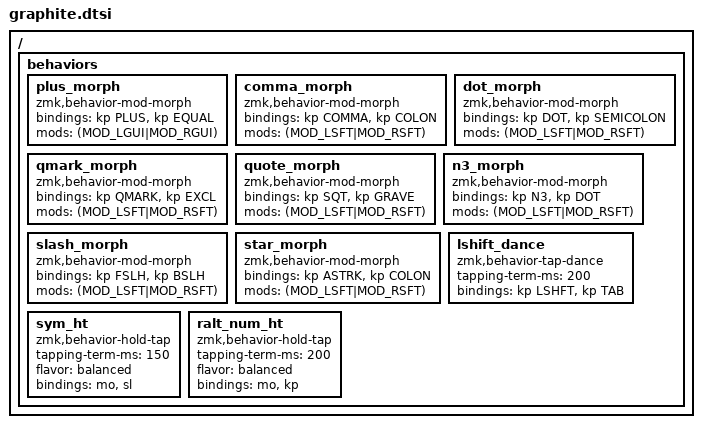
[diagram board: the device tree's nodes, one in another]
/*
 * Graphite Layout - Shared base layer definitions
 * https://github.com/rdavison/graphite-layout
 *
 * Standard Corne (36 keys):
 *   Uses GRAPHITE_BASE_36, GRAPHITE_SYM_36, GRAPHITE_NUM_36, GRAPHITE_SYS_36
 *
 * TOTEM (38 keys):
 *   Uses GRAPHITE_BASE_38, GRAPHITE_SYM_38, GRAPHITE_FUN_38, GRAPHITE_SYS_38
 *
 * Eyelash Corne (42 keys + encoder):
 *   Uses GRAPHITE_BASE_42, GRAPHITE_SYM_42, GRAPHITE_NUM_42, GRAPHITE_SYS_42
 */

// Layer indices
#define BASE 0
#define NUM 1
#define FUN 1  // Corne uses FUN at same index as NUM
#define SYM 2
#define SYS 3
#define NUMSYM 4  // Numpad overlay above SYM (accessed via SYM + %)

/ {
    behaviors {
        plus_morph: plus_morph {
            compatible = "zmk,behavior-mod-morph";
            #binding-cells = <0>;
            bindings = <&kp PLUS>, <&kp EQUAL>;
            mods = <(MOD_LGUI|MOD_RGUI)>;
        };

        comma_morph: comma_morph {
            compatible = "zmk,behavior-mod-morph";
            #binding-cells = <0>;
            bindings = <&kp COMMA>, <&kp COLON>;
            mods = <(MOD_LSFT|MOD_RSFT)>;
        };

        dot_morph: dot_morph {
            compatible = "zmk,behavior-mod-morph";
            #binding-cells = <0>;
            bindings = <&kp DOT>, <&kp SEMICOLON>;
            mods = <(MOD_LSFT|MOD_RSFT)>;
        };

        qmark_morph: qmark_morph {
            compatible = "zmk,behavior-mod-morph";
            #binding-cells = <0>;
            bindings = <&kp QMARK>, <&kp EXCL>;
            mods = <(MOD_LSFT|MOD_RSFT)>;
        };

        quote_morph: quote_morph {
            compatible = "zmk,behavior-mod-morph";
            #binding-cells = <0>;
            bindings = <&kp SQT>, <&kp GRAVE>;
            mods = <(MOD_LSFT|MOD_RSFT)>;
        };

        n3_morph: n3_morph {
            compatible = "zmk,behavior-mod-morph";
            #binding-cells = <0>;
            bindings = <&kp N3>, <&kp DOT>;
            mods = <(MOD_LSFT|MOD_RSFT)>;
        };

        slash_morph: slash_morph {
            compatible = "zmk,behavior-mod-morph";
            #binding-cells = <0>;
            bindings = <&kp FSLH>, <&kp BSLH>;
            mods = <(MOD_LSFT|MOD_RSFT)>;
        };

        star_morph: star_morph {
            compatible = "zmk,behavior-mod-morph";
            #binding-cells = <0>;
            bindings = <&kp ASTRK>, <&kp COLON>;
            mods = <(MOD_LSFT|MOD_RSFT)>;
        };

        lshift_dance: lshift_dance {
            compatible = "zmk,behavior-tap-dance";
            #binding-cells = <0>;
            tapping-term-ms = <200>;
            bindings = <&kp LSHFT>, <&kp TAB>;
        };

        sym_ht: sym_ht {
            compatible = "zmk,behavior-hold-tap";
            #binding-cells = <2>;
            tapping-term-ms = <150>;
            flavor = "balanced";
            bindings = <&mo>, <&sl>;
        };

        ralt_num_ht: ralt_num_ht {
            compatible = "zmk,behavior-hold-tap";
            #binding-cells = <2>;
            tapping-term-ms = <200>;
            flavor = "balanced";
            bindings = <&mo>, <&kp>;
        };
    };
};

// ============================================================================
// 36-KEY LAYOUTS (Standard Corne)
// ============================================================================

#define GRAPHITE_BASE_36 \
   &none           &kp B          &kp L           &kp D           &kp W           &kp Z        &kp SEMI      &kp F           &kp O           &kp U           &kp J           &none          \
   &none           &kp N          &kp R           &kp T           &kp S           &kp G        &kp Y         &kp H           &kp A           &kp E           &kp I           &none          \
   &lshift_dance   &kp Q          &kp X           &kp M           &kp C           &kp V        &kp K         &kp P           &kp COMMA       &kp DOT         &kp FSLH        &kp RSHFT      \
                                               &mt LCTRL ESC   &sym_ht SYM SYM &kp SPC      &kp RET       &kp BSPC        &ralt_num_ht NUM RALT

#define GRAPHITE_SYM_36 \
   &trans          &kp EXCL       &kp LPAR        &kp RPAR        &kp AMPS        &kp GRAVE    &kp COLON     &kp EQUAL       &kp MINUS       &kp PLUS        &kp UNDER       &trans         \
   &trans          &kp ASTRK      &kp LBRC        &kp RBRC        &kp HASH        &kp DOLLAR   &kp PG_UP     &kp LEFT        &kp DOWN        &kp UP          &kp RIGHT       &trans         \
   &trans          &kp CARET      &kp LBKT        &kp RBKT        &kp AT_SIGN     &mo NUMSYM   &kp PG_DN     &kp HOME        &kp END         &kp SQT         &kp BSLH        &trans         \
                                               &kp LCTRL       &trans          &trans       &trans        &kp DEL         &kp LGUI

#define GRAPHITE_NUM_36 \
   &trans          &kp HOME       &kp PG_UP       &kp PG_DN       &kp END         &trans       &star_morph   &kp N7          &kp N8          &kp N9          &kp MINUS       &trans         \
   &trans          &kp LEFT       &kp UP          &kp DOWN        &kp RIGHT       &trans       &kp EQUAL     &kp N4          &kp N5          &kp N6          &kp PLUS        &trans         \
   &kp TAB         &trans         &trans          &trans          &trans          &trans       &kp N0        &kp N1          &kp N2          &n3_morph       &slash_morph    &trans         \
                                               &trans          &trans          &trans       &kp RET       &trans          &trans

#define GRAPHITE_SYS_36 \
   &trans          &out OUT_TOG   &trans          &trans          &trans          &trans       &trans        &kp C_PP        &kp C_NEXT      &trans          &trans          &trans         \
   &trans          &kp PSCRN      &bt BT_SEL 0    &bt BT_SEL 1    &bt BT_SEL 2    &bt BT_SEL 3 &trans        &kp C_VOL_DN    &kp C_VOL_UP    &kp C_BRI_DN    &kp C_BRI_UP    &trans         \
   &trans          &trans         &trans          &trans          &trans          &trans       &trans        &trans          &bt BT_CLR_ALL  &trans          &trans          &trans         \
                                               &trans          &trans          &trans       &trans        &trans          &trans

#define GRAPHITE_NUMSYM_36 \
   &trans          &trans         &trans          &trans          &trans          &trans       &star_morph   &kp N7          &kp N8          &kp N9          &kp MINUS       &trans         \
   &trans          &trans         &trans          &trans          &trans          &trans       &kp EQUAL     &kp N4          &kp N5          &kp N6          &kp PLUS        &trans         \
   &trans          &trans         &trans          &trans          &trans          &trans       &kp N0        &kp N1          &kp N2          &n3_morph       &slash_morph    &trans         \
                                               &trans          &trans          &trans       &kp RET       &trans          &trans

// ============================================================================
// 38-KEY LAYOUTS (TOTEM)
// Format: 5 left | 5 right (row 1 & 2)
//         1 pinky + 5 left | 5 right + 1 pinky (row 3)
//         3 thumb left | 3 thumb right
// ============================================================================

#define GRAPHITE_BASE_38 \
           &kp B          &kp L           &kp D           &kp W           &kp Z        &kp SEMI      &kp F           &kp O           &kp U           &kp J              \
           &kp N          &kp R           &kp T           &kp S           &kp G        &kp Y         &kp H           &kp A           &kp E           &kp I              \
&lshift_dance &kp Q       &kp X           &kp M           &kp C           &kp V        &kp K         &kp P           &kp COMMA       &kp DOT         &kp FSLH    &kp RSHFT \
                                       &mt LCTRL ESC   &sym_ht SYM SYM &kp SPC      &kp RET       &kp BSPC        &ralt_num_ht NUM RALT

#define GRAPHITE_SYM_38 \
           &kp EXCL       &kp LPAR        &kp RPAR        &kp AMPS        &kp GRAVE   &kp COLON    &kp EQUAL       &kp MINUS       &kp PLUS        &kp UNDER          \
           &kp ASTRK      &kp LBRC        &kp RBRC        &kp HASH        &kp DOLLAR   &kp PG_UP     &kp LEFT        &kp DOWN        &kp UP          &kp RIGHT          \
&trans     &kp CARET      &kp LBKT        &kp RBKT        &kp AT_SIGN     &mo NUMSYM        &kp PG_DN     &kp HOME        &kp END         &kp SQT         &kp BSLH  &trans     \
                                       &kp LCTRL       &trans          &trans       &trans        &kp DEL         &kp LGUI

#define GRAPHITE_NUM_38 \
           &kp HOME       &kp PG_UP       &kp PG_DN       &kp END         &trans       &star_morph   &kp N7          &kp N8          &kp N9          &kp MINUS          \
           &kp LEFT       &kp UP          &kp DOWN        &kp RIGHT       &trans       &kp EQUAL     &kp N4          &kp N5          &kp N6          &kp PLUS           \
&kp TAB    &trans         &trans          &trans          &trans          &trans       &kp N0        &kp N1          &kp N2          &n3_morph       &slash_morph  &trans     \
                                       &trans          &trans          &trans       &kp RET       &trans          &trans

#define GRAPHITE_FUN_38 \
           &kp F1         &kp F2          &kp F3          &kp F4          &kp F5       &kp F6        &kp F7          &kp F8          &kp F9          &kp F10            \
           &trans         &trans          &trans          &trans          &trans       &trans        &trans          &trans          &trans          &kp F11            \
&trans     &trans         &trans          &trans          &trans          &trans       &trans        &trans          &trans          &trans          &trans    &kp F12  \
                                       &trans          &trans          &trans       &trans        &trans          &trans

#define GRAPHITE_SYS_38 \
           &out OUT_TOG   &trans          &trans          &trans          &trans       &trans        &kp C_PP        &kp C_NEXT      &trans          &trans             \
           &kp PSCRN      &bt BT_SEL 0    &bt BT_SEL 1    &bt BT_SEL 2    &bt BT_SEL 3 &trans        &kp C_VOL_DN    &kp C_VOL_UP    &kp C_BRI_DN    &kp C_BRI_UP       \
&trans     &trans         &trans          &trans          &trans          &trans       &trans        &trans          &bt BT_CLR_ALL  &trans          &trans    &trans     \
                                       &trans          &trans          &trans       &trans        &trans          &trans

#define GRAPHITE_NUMSYM_38 \
           &trans         &trans          &trans          &trans          &trans       &star_morph   &kp N7          &kp N8          &kp N9          &kp MINUS          \
           &trans         &trans          &trans          &trans          &trans       &kp EQUAL     &kp N4          &kp N5          &kp N6          &kp PLUS           \
&trans     &trans         &trans          &trans          &trans          &trans       &kp N0        &kp N1          &kp N2          &n3_morph       &slash_morph  &trans     \
                                       &trans          &trans          &trans       &kp RET       &trans          &trans

// ============================================================================
// 42-KEY LAYOUTS (Eyelash Corne with joystick + encoder)
// Format: 6 left | 1 encoder | 6 right (row 1)
//         6 left | 3 joystick | 6 right (row 2)
//         6 left | 1 extra | 1 encoder | 6 right (row 3)
//         3 thumb left | 3 thumb right
// ============================================================================

#define GRAPHITE_BASE_42 \
&none         &kp B      &kp L  &kp D     &kp W       &kp Z                                  &kp UP                   &kp SEMI       &kp F   &kp O      &kp U      &kp J     &none       \
&none         &kp N      &kp R  &kp T     &kp S       &kp G                        &kp LEFT  &kp ENTER   &kp RIGHT   &kp Y          &kp H   &kp A      &kp E      &kp I     &none       \
&lshift_dance &kp Q      &kp X  &kp M     &kp C       &kp V       &kp SPACE                  &kp DOWN                &kp K          &kp P   &kp COMMA  &kp DOT    &kp FSLH  &kp RSHFT   \
                                &mt LCTRL ESC &sym_ht SYM SYM &kp SPC                                                &kp RET        &kp BSPC &ralt_num_ht NUM RALT

#define GRAPHITE_SYM_42 \
&trans  &kp EXCL    &kp LPAR  &kp RPAR  &kp AMPS  &kp GRAVE                                    &mmv MOVE_UP                  &kp COLON  &kp EQUAL  &kp MINUS  &kp PLUS  &kp UNDER &trans      \
&trans  &kp ASTRK   &kp LBRC  &kp RBRC  &kp HASH  &kp DOLLAR                  &mmv MOVE_LEFT &mkp LCLK    &mmv MOVE_RIGHT  &kp PG_UP  &kp LEFT   &kp DOWN  &kp UP     &kp RIGHT &trans      \
&trans  &kp CARET   &kp LBKT  &kp RBKT  &kp AT_SIGN &mo NUMSYM &kp C_MUTE                    &mmv MOVE_DOWN                &kp PG_DN  &kp HOME   &kp END   &kp SQT    &kp BSLH  &trans      \
                              &kp LCTRL &trans    &trans                                                                   &trans     &kp DEL    &kp LGUI

#define GRAPHITE_NUM_42 \
&trans  &kp HOME    &kp PG_UP  &kp PG_DN    &kp END    &trans                                &mmv MOVE_UP                  &star_morph  &kp N7     &kp N8       &kp N9      &kp MINUS        &trans        \
&trans  &kp LEFT    &kp UP     &kp DOWN     &kp RIGHT  &trans                &mmv MOVE_LEFT  &mkp LCLK    &mmv MOVE_RIGHT  &kp EQUAL    &kp N4     &kp N5       &kp N6      &kp PLUS         &trans        \
&trans  &trans      &trans     &trans       &trans     &trans    &kp C_MUTE                  &mmv MOVE_DOWN                &kp N0       &kp N1     &kp N2       &n3_morph   &slash_morph     &trans        \
                               &trans       &trans     &trans                                                              &kp RET      &trans     &trans

#define GRAPHITE_SYS_42 \
&trans  &trans           &out OUT_TOG    &kp C_BRI_DN  &kp C_BRI_UP  &kp C_PP                                    &mmv MOVE_UP                  &kp C_NEXT       &kp C_VOL_UP     &kp C_VOL_DN     &trans           &trans    &trans    \
&trans  &bt BT_CLR_ALL   &bt BT_SEL 0    &bt BT_SEL 1  &bt BT_SEL 2  &bt BT_SEL 3                 &mmv MOVE_LEFT  &mkp LCLK    &mmv MOVE_RIGHT  &trans           &trans           &trans           &trans           &trans    &trans    \
&trans  &rgb_ug RGB_OFF  &rgb_ug RGB_ON  &trans        &trans        &rgb_ug RGB_EFF &kp C_MUTE                   &mmv MOVE_DOWN                &rgb_ug RGB_EFR  &rgb_ug RGB_SPI  &rgb_ug RGB_BRI  &rgb_ug RGB_BRD  &trans    &trans    \
                                         &trans        &trans        &trans                                                                     &trans           &trans           &trans

#define GRAPHITE_NUMSYM_42 \
&trans  &trans      &trans     &trans       &trans     &trans                                    &mmv MOVE_UP                  &star_morph  &kp N7     &kp N8       &kp N9      &kp MINUS        &trans        \
&trans  &trans      &trans     &trans       &trans     &trans                    &mmv MOVE_LEFT  &mkp LCLK    &mmv MOVE_RIGHT  &kp EQUAL    &kp N4     &kp N5       &kp N6      &kp PLUS         &trans        \
&trans  &trans      &trans     &trans       &trans     &trans    &kp C_MUTE                     &mmv MOVE_DOWN                &kp N0       &kp N1     &kp N2       &n3_morph   &slash_morph     &trans        \
                               &trans       &trans     &trans                                                                 &kp RET      &trans     &trans
